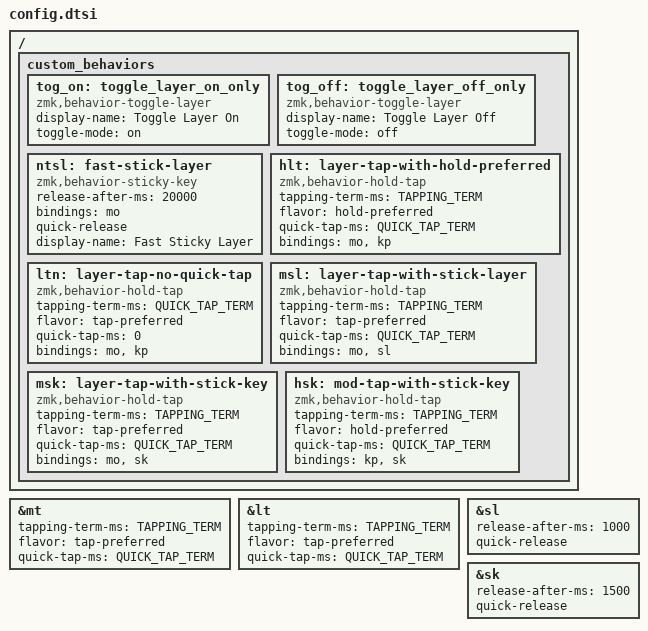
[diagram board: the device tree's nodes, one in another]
/*
 *
 * Copyright (c) 2022 Rafael Romão
 * SPDX-License-Identifier: MIT
 *
 */

 // Layers

#define ALPHA1 0
#define ALT_OS 1

#define MEHS 2

#define VIM_NORMAL 3
#define VIM_VISUAL 4
#define VIM_CHANGE 5
#define VIM_LEADER 6
#define VIM_INSERT 7
#define VIM_REPLACE 8
#define VIM_CMDLINE 9

#define CASE_A1 10
#define CPLK_A1 11

#define ALPHA2 12

#define NUM 13
#define SYM 14

#define SEN_CASE 15
#define CCEDIL 16
#define SFT_A2 17
#define CASE_A2 18
#define CASE_CCEDIL 19

#define SHORTS 20
#define TOGS 21

#define ALTREP2 22

#define NAV 23

#define NUM_CP 24
#define SYM_CP 25

#define MEDIA 26
#define NAV_CP 27

#define TEXT 28
#define FUN 29
#define MACROS 30


// Mod morphs

#define MOD_ALL MOD_LALT|MOD_RALT|MOD_LCTL|MOD_RCTL|MOD_LSFT|MOD_RSFT|MOD_LGUI|MOD_RGUI

// Settings

#define COMBO_TERM 30
#define TAPPING_TERM 250
#define QUICK_TAP_TERM 175
#define ADAPTIVE_KEY_TIMEOUT 2000

/*                KEY POSITIONS

  ╭─────────────────────╮ ╭─────────────────────╮
  │ LTP LTR LTM LTI LTC │ │ RTC RTI RTM RTR RTP │
  │ LHP LHR LHM LHI LHC │ │ RHC RHI RHM RHR RHP │
  │ LBP LBR LBM LBI LBC │ │ RBC RBI RBM RBR RBP │
  ╰───────╮ L2  L1  L0  │ │ R0  R1  R2  ╭───────╯
          ╰─────────────╯ ╰─────────────╯ 
  ╭─────────────────────╮ ╭─────────────────────╮
  │  0   1   2   3   4  │ │   5   6   7   8   9 │
  │ 10  11  12  13  14  │ │  15  16  17  18  19 │
  │ 20  21  22  23  24  │ │  25  26  27  28  29 │
  ╰──────╮  30  31  32  │ │  33  34  35 ╭───────╯
         ╰──────────────╯ ╰─────────────╯

*/

#define LTP 0   // left-top row
#define LTR 1
#define LTM 2
#define LTI 3
#define LTC 4  

#define RTC 5   // right-top row
#define RTI 6
#define RTM 7
#define RTR 8
#define RTP 9

#define LHP 10  // left-middle row
#define LHR 11
#define LHM 12
#define LHI 13
#define LHC 14

#define RHC 15  // right-middle row
#define RHI 16
#define RHM 17
#define RHR 18
#define RHP 19

#define LBP 20  // left-bottom row
#define LBR 21
#define LBM 22
#define LBI 23
#define LBC 24

#define RBC 25  // right-bottom row
#define RBI 26
#define RBM 27
#define RBR 28
#define RBP 29

#define L2  30  // left thumb keys
#define L1  31
#define L0  32

#define R0  33  // right thumb keys
#define R1  34
#define R2  35

&mt {
    tapping-term-ms = <TAPPING_TERM>;
    flavor = "tap-preferred";
    quick-tap-ms = <QUICK_TAP_TERM>;
};

&lt {
    tapping-term-ms = <TAPPING_TERM>;
    flavor = "tap-preferred";
    quick-tap-ms = <QUICK_TAP_TERM>;
};

&sl {
    release-after-ms = <1000>;
    quick-release;
};

&sk {
    release-after-ms = <1500>;
    quick-release;
};

/ {
    custom_behaviors {

        tog_on: toggle_layer_on_only {
            compatible = "zmk,behavior-toggle-layer";
            #binding-cells = <1>;
            display-name = "Toggle Layer On";
            toggle-mode = "on";
        };

        tog_off: toggle_layer_off_only {
            compatible = "zmk,behavior-toggle-layer";
            #binding-cells = <1>;
            display-name = "Toggle Layer Off";
            toggle-mode = "off";
        };

        ntsl: fast-stick-layer {
            compatible = "zmk,behavior-sticky-key";
            #binding-cells = <1>;
            release-after-ms = <20000>;
            bindings = <&mo>;
            quick-release;
            display-name = "Fast Sticky Layer";
        };

        hlt: layer-tap-with-hold-preferred {
            compatible = "zmk,behavior-hold-tap";
            #binding-cells = <2>;
            tapping-term-ms = <TAPPING_TERM>;
            flavor = "hold-preferred";
            quick-tap-ms = <QUICK_TAP_TERM>;
            bindings = <&mo>, <&kp>;
        };

        ltn: layer-tap-no-quick-tap {
            compatible = "zmk,behavior-hold-tap";
            #binding-cells = <2>;
            tapping-term-ms = <QUICK_TAP_TERM>;
            flavor = "tap-preferred";
            quick-tap-ms = <0>;
            bindings = <&mo>, <&kp>;
        };

        msl: layer-tap-with-stick-layer {
            compatible = "zmk,behavior-hold-tap";
            #binding-cells = <2>;
            tapping-term-ms = <TAPPING_TERM>;
            flavor = "tap-preferred";
            quick-tap-ms = <QUICK_TAP_TERM>;
            bindings = <&mo>, <&sl>;
        };

        msk: layer-tap-with-stick-key {
            compatible = "zmk,behavior-hold-tap";
            #binding-cells = <2>;
            tapping-term-ms = <TAPPING_TERM>;
            flavor = "tap-preferred";
            quick-tap-ms = <QUICK_TAP_TERM>;
            bindings = <&mo>, <&sk>;
        };

        hsk: mod-tap-with-stick-key {
            compatible = "zmk,behavior-hold-tap";
            #binding-cells = <2>;
            tapping-term-ms = <TAPPING_TERM>;
            flavor = "hold-preferred";
            quick-tap-ms = <QUICK_TAP_TERM>;
            bindings = <&kp>, <&sk>;
        };

    };
};
